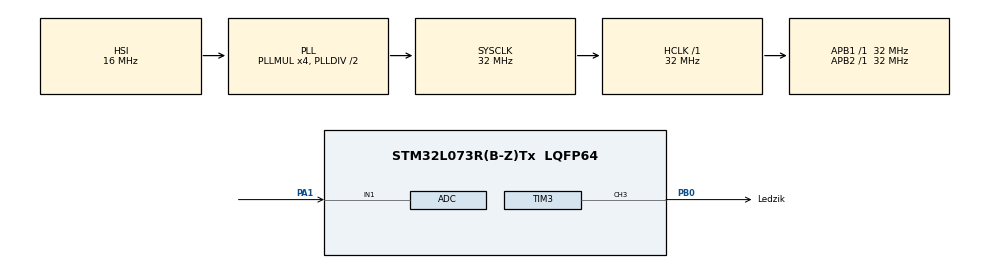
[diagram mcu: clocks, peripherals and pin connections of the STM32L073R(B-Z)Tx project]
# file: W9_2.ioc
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ADC.ContinuousConvMode=ENABLE
ADC.DMAContinuousRequests=ENABLE
ADC.DiscontinuousConvMode=DISABLE
ADC.Overrun=ADC_OVR_DATA_OVERWRITTEN
Dma.ADC.0.Direction=DMA_PERIPH_TO_MEMORY
Dma.ADC.0.Instance=DMA1_Channel1
Dma.ADC.0.MemDataAlignment=DMA_MDATAALIGN_HALFWORD
Dma.ADC.0.MemInc=DMA_MINC_ENABLE
Dma.ADC.0.Mode=DMA_CIRCULAR
Dma.ADC.0.PeriphDataAlignment=DMA_PDATAALIGN_HALFWORD
Dma.ADC.0.PeriphInc=DMA_PINC_DISABLE
Dma.ADC.0.Priority=DMA_PRIORITY_LOW
Dma.Request0=ADC
Mcu.Family=STM32L0
Mcu.Name=STM32L073R(B-Z)Tx
Mcu.Package=LQFP64
NVIC.DMA1_Channel1_IRQn=true\:0\:0\:false\:false\:true\:false\:true\:true
PA1.Mode=IN1
PA1.Signal=ADC_IN1
PB0.GPIO_Label=Ledzik
PB0.Signal=S_TIM3_CH3
ProjectManager.HeapSize=0x200
ProjectManager.StackSize=0x400
ProjectManager.TargetToolchain=STM32CubeIDE
RCC.AHBFreq_Value=32000000
RCC.APB1Freq_Value=32000000
RCC.APB1TimFreq_Value=32000000
RCC.APB2Freq_Value=32000000
RCC.APB2TimFreq_Value=32000000
RCC.HCLKFreq_Value=32000000
RCC.HSE_VALUE=8000000
RCC.HSI16_VALUE=16000000
RCC.HSI48_VALUE=48000000
RCC.HSI_VALUE=16000000
RCC.LSE_VALUE=32768
RCC.MSI_VALUE=2097000
RCC.PLLMUL=RCC_PLLMUL_4
RCC.SYSCLKFreq_VALUE=32000000
RCC.SYSCLKSource=RCC_SYSCLKSOURCE_PLLCLK
RCC.VCOOutputFreq_Value=64000000
SH.S_TIM3_CH3.0=TIM3_CH3,PWM Generation3 CH3
TIM3.Channel-PWM\ Generation3\ CH3=TIM_CHANNEL_3
TIM3.Period=1000-1
TIM3.Prescaler=32-1
VP_TIM3_VS_ClockSourceINT.Mode=Internal
board=custom

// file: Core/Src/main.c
/* USER CODE BEGIN Header */
/**
  ******************************************************************************
  * @file           : main.c
  * @brief          : Main program body
  ******************************************************************************
  * @attention
  *
  * Copyright (c) 2023 STMicroelectronics.
  * All rights reserved.
  *
  * This software is licensed under terms that can be found in the LICENSE file
  * in the root directory of this software component.
  * If no LICENSE file comes with this software, it is provided AS-IS.
  *
  ******************************************************************************
  */
/* USER CODE END Header */
#include "main.h"

 ADC_HandleTypeDef hadc;
DMA_HandleTypeDef hdma_adc;

TIM_HandleTypeDef htim3;

/* USER CODE BEGIN PV */
volatile static uint32_t value[1];
/* USER CODE END PV */

void SystemClock_Config(void);
static void MX_GPIO_Init(void);
static void MX_DMA_Init(void);
static void MX_TIM3_Init(void);
static void MX_ADC_Init(void);

/* USER CODE BEGIN 0 */
void HAL_ADC_ConvHalfCpltCallback(ADC_HandleTypeDef* hadc){
	HAL_GPIO_WritePin(Ledzik_GPIO_Port, Ledzik_Pin, GPIO_PIN_SET);
	htim3.Instance->CCR3 = (value[0]-1700)/3+200;
}

void HAL_ADC_ConvCpltCallback(ADC_HandleTypeDef* hadc){
	HAL_GPIO_WritePin(Ledzik_GPIO_Port, Ledzik_Pin, GPIO_PIN_RESET);
}
/* USER CODE END 0 */

int main(void)
{

  /* MCU Configuration--------------------------------------------------------*/

  /* Reset of all peripherals, Initializes the Flash interface and the Systick. */
  HAL_Init();

  /* Configure the system clock */
  SystemClock_Config();

  /* Initialize all configured peripherals */
  MX_GPIO_Init();
  MX_DMA_Init();
  MX_TIM3_Init();
  MX_ADC_Init();
  /* USER CODE BEGIN 2 */

  HAL_ADCEx_Calibration_Start(&hadc, ADC_SINGLE_ENDED);
  HAL_ADC_Start_DMA(&hadc, (uint32_t*)value, 1);
  HAL_TIM_Base_Start(&htim3);
  HAL_TIM_PWM_Start(&htim3, TIM_CHANNEL_3);
htim3.Instance->CCR3 = 0;

  /* USER CODE END 2 */

  /* Infinite loop */
  while (1)
  {

    /* USER CODE BEGIN 3 */

	//  HAL_Delay(100);
  }
  /* USER CODE END 3 */
}

void SystemClock_Config(void)
{
  RCC_OscInitTypeDef RCC_OscInitStruct = {0};
  RCC_ClkInitTypeDef RCC_ClkInitStruct = {0};

  /** Configure the main internal regulator output voltage
  */
  __HAL_PWR_VOLTAGESCALING_CONFIG(PWR_REGULATOR_VOLTAGE_SCALE1);

  /** Initializes the RCC Oscillators according to the specified parameters
  * in the RCC_OscInitTypeDef structure.
  */
  RCC_OscInitStruct.OscillatorType = RCC_OSCILLATORTYPE_HSI;
  RCC_OscInitStruct.HSIState = RCC_HSI_ON;
  RCC_OscInitStruct.HSICalibrationValue = RCC_HSICALIBRATION_DEFAULT;
  RCC_OscInitStruct.PLL.PLLState = RCC_PLL_ON;
  RCC_OscInitStruct.PLL.PLLSource = RCC_PLLSOURCE_HSI;
  RCC_OscInitStruct.PLL.PLLMUL = RCC_PLLMUL_4;
  RCC_OscInitStruct.PLL.PLLDIV = RCC_PLLDIV_2;
  if (HAL_RCC_OscConfig(&RCC_OscInitStruct) != HAL_OK)
  {
    Error_Handler();
  }

  /** Initializes the CPU, AHB and APB buses clocks
  */
  RCC_ClkInitStruct.ClockType = RCC_CLOCKTYPE_HCLK|RCC_CLOCKTYPE_SYSCLK
                              |RCC_CLOCKTYPE_PCLK1|RCC_CLOCKTYPE_PCLK2;
  RCC_ClkInitStruct.SYSCLKSource = RCC_SYSCLKSOURCE_PLLCLK;
  RCC_ClkInitStruct.AHBCLKDivider = RCC_SYSCLK_DIV1;
  RCC_ClkInitStruct.APB1CLKDivider = RCC_HCLK_DIV1;
  RCC_ClkInitStruct.APB2CLKDivider = RCC_HCLK_DIV1;

  if (HAL_RCC_ClockConfig(&RCC_ClkInitStruct, FLASH_LATENCY_1) != HAL_OK)
  {
    Error_Handler();
  }
}

static void MX_ADC_Init(void)
{

  ADC_ChannelConfTypeDef sConfig = {0};

  /** Configure the global features of the ADC (Clock, Resolution, Data Alignment and number of conversion)
  */
  hadc.Instance = ADC1;
  hadc.Init.OversamplingMode = DISABLE;
  hadc.Init.ClockPrescaler = ADC_CLOCK_SYNC_PCLK_DIV2;
  hadc.Init.Resolution = ADC_RESOLUTION_12B;
  hadc.Init.SamplingTime = ADC_SAMPLETIME_1CYCLE_5;
  hadc.Init.ScanConvMode = ADC_SCAN_DIRECTION_FORWARD;
  hadc.Init.DataAlign = ADC_DATAALIGN_RIGHT;
  hadc.Init.ContinuousConvMode = ENABLE;
  hadc.Init.DiscontinuousConvMode = DISABLE;
  hadc.Init.ExternalTrigConvEdge = ADC_EXTERNALTRIGCONVEDGE_NONE;
  hadc.Init.ExternalTrigConv = ADC_SOFTWARE_START;
  hadc.Init.DMAContinuousRequests = ENABLE;
  hadc.Init.EOCSelection = ADC_EOC_SINGLE_CONV;
  hadc.Init.Overrun = ADC_OVR_DATA_OVERWRITTEN;
  hadc.Init.LowPowerAutoWait = DISABLE;
  hadc.Init.LowPowerFrequencyMode = DISABLE;
  hadc.Init.LowPowerAutoPowerOff = DISABLE;
  if (HAL_ADC_Init(&hadc) != HAL_OK)
  {
    Error_Handler();
  }

  /** Configure for the selected ADC regular channel to be converted.
  */
  sConfig.Channel = ADC_CHANNEL_1;
  sConfig.Rank = ADC_RANK_CHANNEL_NUMBER;
  if (HAL_ADC_ConfigChannel(&hadc, &sConfig) != HAL_OK)
  {
    Error_Handler();
  }

}

static void MX_TIM3_Init(void)
{

  TIM_ClockConfigTypeDef sClockSourceConfig = {0};
  TIM_MasterConfigTypeDef sMasterConfig = {0};
  TIM_OC_InitTypeDef sConfigOC = {0};

  htim3.Instance = TIM3;
  htim3.Init.Prescaler = 32-1;
  htim3.Init.CounterMode = TIM_COUNTERMODE_UP;
  htim3.Init.Period = 1000-1;
  htim3.Init.ClockDivision = TIM_CLOCKDIVISION_DIV1;
  htim3.Init.AutoReloadPreload = TIM_AUTORELOAD_PRELOAD_DISABLE;
  if (HAL_TIM_Base_Init(&htim3) != HAL_OK)
  {
    Error_Handler();
  }
  sClockSourceConfig.ClockSource = TIM_CLOCKSOURCE_INTERNAL;
  if (HAL_TIM_ConfigClockSource(&htim3, &sClockSourceConfig) != HAL_OK)
  {
    Error_Handler();
  }
  if (HAL_TIM_PWM_Init(&htim3) != HAL_OK)
  {
    Error_Handler();
  }
  sMasterConfig.MasterOutputTrigger = TIM_TRGO_RESET;
  sMasterConfig.MasterSlaveMode = TIM_MASTERSLAVEMODE_DISABLE;
  if (HAL_TIMEx_MasterConfigSynchronization(&htim3, &sMasterConfig) != HAL_OK)
  {
    Error_Handler();
  }
  sConfigOC.OCMode = TIM_OCMODE_PWM1;
  sConfigOC.Pulse = 0;
  sConfigOC.OCPolarity = TIM_OCPOLARITY_HIGH;
  sConfigOC.OCFastMode = TIM_OCFAST_DISABLE;
  if (HAL_TIM_PWM_ConfigChannel(&htim3, &sConfigOC, TIM_CHANNEL_3) != HAL_OK)
  {
    Error_Handler();
  }
  HAL_TIM_MspPostInit(&htim3);

}

static void MX_DMA_Init(void)
{

  /* DMA controller clock enable */
  __HAL_RCC_DMA1_CLK_ENABLE();

  /* DMA interrupt init */
  /* DMA1_Channel1_IRQn interrupt configuration */
  HAL_NVIC_SetPriority(DMA1_Channel1_IRQn, 0, 0);
  HAL_NVIC_EnableIRQ(DMA1_Channel1_IRQn);

}

static void MX_GPIO_Init(void)
{

  /* GPIO Ports Clock Enable */
  __HAL_RCC_GPIOA_CLK_ENABLE();
  __HAL_RCC_GPIOB_CLK_ENABLE();

}

void Error_Handler(void)
{
  __disable_irq();
  while (1)
  {
  }
}
